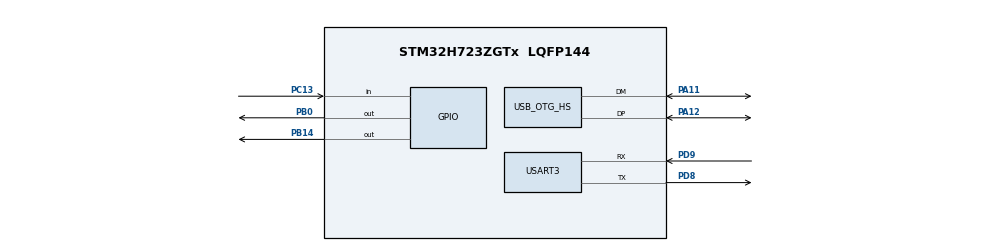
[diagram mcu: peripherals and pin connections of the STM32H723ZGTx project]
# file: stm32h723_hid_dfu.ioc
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CORTEX_M7.default_mode_Activation=1
Mcu.Family=STM32H7
Mcu.Name=STM32H723ZGTx
Mcu.Package=LQFP144
NVIC.OTG_HS_IRQn=true\:0\:0\:false\:false\:true\:false\:true\:true
NVIC.PriorityGroup=NVIC_PRIORITYGROUP_4
PA11.Mode=Device_Only_FS
PA11.Signal=USB_OTG_HS_DM
PA12.Mode=Device_Only_FS
PA12.Signal=USB_OTG_HS_DP
PA13(JTMS/SWDIO).Mode=Serial_Wire
PA13(JTMS/SWDIO).Signal=DEBUG_JTMS-SWDIO
PA14(JTCK/SWCLK).Mode=Serial_Wire
PA14(JTCK/SWCLK).Signal=DEBUG_JTCK-SWCLK
PB0.Signal=GPIO_Output
PB14.Signal=GPIO_Output
PC13.Signal=GPIO_Input
PD8.Mode=Asynchronous
PD8.Signal=USART3_TX
PD9.Mode=Asynchronous
PD9.Signal=USART3_RX
ProjectManager.HeapSize=0x400
ProjectManager.StackSize=0x800
ProjectManager.TargetToolchain=STM32CubeIDE
RCC.ADCFreq_Value=129000000
RCC.APB1Freq_Value=137500000
RCC.APB2Freq_Value=137500000
RCC.APB3Freq_Value=137500000
RCC.APB4Freq_Value=137500000
RCC.CortexFreq_Value=550000000
RCC.D1PPRE=RCC_APB3_DIV2
RCC.D2PPRE1=RCC_APB1_DIV2
RCC.D2PPRE2=RCC_APB2_DIV2
RCC.D3PPRE=RCC_APB4_DIV2
RCC.DIVM1=4
RCC.DIVN1=34
RCC.DIVP1=1
RCC.HCLKFreq_Value=275000000
RCC.HPRE=RCC_HCLK_DIV2
RCC.PLL2FRACN=0
RCC.PLL3FRACN=0
RCC.PLLFRACN=3072
RCC.SYSCLKFreq_VALUE=550000000
RCC.SYSCLKSource=RCC_SYSCLKSOURCE_PLLCLK
RCC.USBCLockSelection=RCC_USBCLKSOURCE_HSI48
RCC.USBFreq_Value=48000000
USART3.VirtualMode-Asynchronous=VM_ASYNC
USB_DEVICE.CLASS_NAME_HS=CUSTOM_HID
USB_DEVICE.USBD_CUSTOMHID_OUTREPORT_BUF_SIZE=64
USB_DEVICE.USBD_CUSTOM_HID_REPORT_DESC_SIZE=33
USB_DEVICE.VirtualMode=CustomHid
USB_DEVICE.VirtualModeHS=Custom_Hid_HS
USB_OTG_HS.VirtualMode-Device_Only_FS=Device_Only_FS
VP_USB_DEVICE_VS_USB_DEVICE_CUSTOM_HID_HS.Mode=CUSTOM_HID_HS
board=custom

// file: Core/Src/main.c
/* USER CODE BEGIN Header */
/**
  ******************************************************************************
  * @file           : main.c
  * @brief          : Main program body
  ******************************************************************************
  * @attention
  *
  * Copyright (c) 2024 STMicroelectronics.
  * All rights reserved.
  *
  * This software is licensed under terms that can be found in the LICENSE file
  * in the root directory of this software component.
  * If no LICENSE file comes with this software, it is provided AS-IS.
  *
  ******************************************************************************
  */
/* USER CODE END Header */
#include "main.h"
#include "usart.h"
#include "usb_device.h"
#include "gpio.h"

/* USER CODE BEGIN Includes */
#include "usbd_custom_hid_if.h"
/* USER CODE END Includes */

void SystemClock_Config(void);
static void MPU_Config(void);

/* USER CODE BEGIN 0 */
extern USBD_HandleTypeDef hUsbDeviceHS;
static uint8_t USB_TxBuffer[64];
/* USER CODE END 0 */

int main(void)
{

  /* MPU Configuration--------------------------------------------------------*/
  MPU_Config();

  /* MCU Configuration--------------------------------------------------------*/

  /* Reset of all peripherals, Initializes the Flash interface and the Systick. */
  HAL_Init();

  /* Configure the system clock */
  SystemClock_Config();

  /* Initialize all configured peripherals */
  MX_GPIO_Init();
  MX_USART3_UART_Init();
  MX_USB_DEVICE_Init();

  /* Infinite loop */
  /* USER CODE BEGIN WHILE */
  while (1)
  {
		if (HAL_GPIO_ReadPin(GPIOC, GPIO_PIN_13)==GPIO_PIN_SET) {
			for (int i = 0; i < 64; i++) {
				USB_TxBuffer[i] = i;
			}
			USBD_CUSTOM_HID_SendReport(&hUsbDeviceHS, USB_TxBuffer, 64);
		}
    /* USER CODE END WHILE */

  }
}

void SystemClock_Config(void)
{
  RCC_OscInitTypeDef RCC_OscInitStruct = {0};
  RCC_ClkInitTypeDef RCC_ClkInitStruct = {0};

  /** Supply configuration update enable
  */
  HAL_PWREx_ConfigSupply(PWR_LDO_SUPPLY);

  /** Configure the main internal regulator output voltage
  */
  __HAL_PWR_VOLTAGESCALING_CONFIG(PWR_REGULATOR_VOLTAGE_SCALE0);

  while(!__HAL_PWR_GET_FLAG(PWR_FLAG_VOSRDY)) {}

  /** Initializes the RCC Oscillators according to the specified parameters
  * in the RCC_OscInitTypeDef structure.
  */
  RCC_OscInitStruct.OscillatorType = RCC_OSCILLATORTYPE_HSI48|RCC_OSCILLATORTYPE_HSI;
  RCC_OscInitStruct.HSIState = RCC_HSI_DIV1;
  RCC_OscInitStruct.HSICalibrationValue = 64;
  RCC_OscInitStruct.HSI48State = RCC_HSI48_ON;
  RCC_OscInitStruct.PLL.PLLState = RCC_PLL_ON;
  RCC_OscInitStruct.PLL.PLLSource = RCC_PLLSOURCE_HSI;
  RCC_OscInitStruct.PLL.PLLM = 4;
  RCC_OscInitStruct.PLL.PLLN = 34;
  RCC_OscInitStruct.PLL.PLLP = 1;
  RCC_OscInitStruct.PLL.PLLQ = 2;
  RCC_OscInitStruct.PLL.PLLR = 2;
  RCC_OscInitStruct.PLL.PLLRGE = RCC_PLL1VCIRANGE_3;
  RCC_OscInitStruct.PLL.PLLVCOSEL = RCC_PLL1VCOWIDE;
  RCC_OscInitStruct.PLL.PLLFRACN = 3072;
  if (HAL_RCC_OscConfig(&RCC_OscInitStruct) != HAL_OK)
  {
    Error_Handler();
  }

  /** Initializes the CPU, AHB and APB buses clocks
  */
  RCC_ClkInitStruct.ClockType = RCC_CLOCKTYPE_HCLK|RCC_CLOCKTYPE_SYSCLK
                              |RCC_CLOCKTYPE_PCLK1|RCC_CLOCKTYPE_PCLK2
                              |RCC_CLOCKTYPE_D3PCLK1|RCC_CLOCKTYPE_D1PCLK1;
  RCC_ClkInitStruct.SYSCLKSource = RCC_SYSCLKSOURCE_PLLCLK;
  RCC_ClkInitStruct.SYSCLKDivider = RCC_SYSCLK_DIV1;
  RCC_ClkInitStruct.AHBCLKDivider = RCC_HCLK_DIV2;
  RCC_ClkInitStruct.APB3CLKDivider = RCC_APB3_DIV2;
  RCC_ClkInitStruct.APB1CLKDivider = RCC_APB1_DIV2;
  RCC_ClkInitStruct.APB2CLKDivider = RCC_APB2_DIV2;
  RCC_ClkInitStruct.APB4CLKDivider = RCC_APB4_DIV2;

  if (HAL_RCC_ClockConfig(&RCC_ClkInitStruct, FLASH_LATENCY_3) != HAL_OK)
  {
    Error_Handler();
  }
}

 /* MPU Configuration */

void MPU_Config(void)
{
  MPU_Region_InitTypeDef MPU_InitStruct = {0};

  /* Disables the MPU */
  HAL_MPU_Disable();

  /** Initializes and configures the Region and the memory to be protected
  */
  MPU_InitStruct.Enable = MPU_REGION_ENABLE;
  MPU_InitStruct.Number = MPU_REGION_NUMBER0;
  MPU_InitStruct.BaseAddress = 0x0;
  MPU_InitStruct.Size = MPU_REGION_SIZE_4GB;
  MPU_InitStruct.SubRegionDisable = 0x87;
  MPU_InitStruct.TypeExtField = MPU_TEX_LEVEL0;
  MPU_InitStruct.AccessPermission = MPU_REGION_NO_ACCESS;
  MPU_InitStruct.DisableExec = MPU_INSTRUCTION_ACCESS_DISABLE;
  MPU_InitStruct.IsShareable = MPU_ACCESS_SHAREABLE;
  MPU_InitStruct.IsCacheable = MPU_ACCESS_NOT_CACHEABLE;
  MPU_InitStruct.IsBufferable = MPU_ACCESS_NOT_BUFFERABLE;

  HAL_MPU_ConfigRegion(&MPU_InitStruct);
  /* Enables the MPU */
  HAL_MPU_Enable(MPU_PRIVILEGED_DEFAULT);

}

void Error_Handler(void)
{
  __disable_irq();
  while (1)
  {
  }
}
